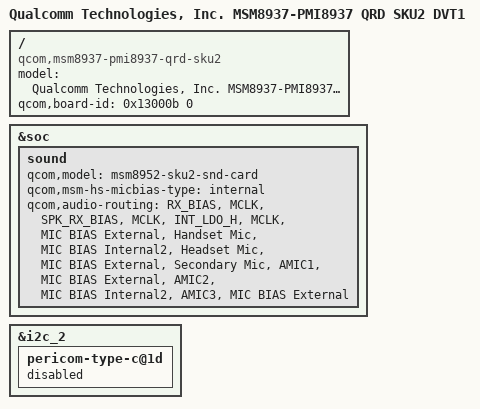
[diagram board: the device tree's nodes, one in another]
/*
 * Copyright (c) 2015, The Linux Foundation. All rights reserved.
 *
 * This program is free software; you can redistribute it and/or modify
 * it under the terms of the GNU General Public License version 2 and
 * only version 2 as published by the Free Software Foundation.
 *
 * This program is distributed in the hope that it will be useful,
 * but WITHOUT ANY WARRANTY; without even the implied warranty of
 * MERCHANTABILITY or FITNESS FOR A PARTICULAR PURPOSE.  See the
 * GNU General Public License for more details.
 */

/dts-v1/;

#include "msm8937.dtsi"
#include "msm8937-pmi8937-qrd-sku2.dtsi"

/ {
	model = "Qualcomm Technologies, Inc. MSM8937-PMI8937 QRD SKU2 DVT1";
	compatible = "qcom,msm8937-pmi8937-qrd-sku2",
		   "qcom,msm8937-qrd", "qcom,msm8937", "qcom,qrd";
	qcom,board-id= <0x13000b 0>;
};

&soc {
	sound {
		qcom,model = "msm8952-sku2-snd-card";
		qcom,msm-hs-micbias-type = "internal";
		qcom,audio-routing =
			"RX_BIAS", "MCLK",
			"SPK_RX_BIAS", "MCLK",
			"INT_LDO_H", "MCLK",
			"MIC BIAS External", "Handset Mic",
			"MIC BIAS Internal2", "Headset Mic",
			"MIC BIAS External", "Secondary Mic",
			"AMIC1", "MIC BIAS External",
			"AMIC2", "MIC BIAS Internal2",
			"AMIC3", "MIC BIAS External";
	};
};

&i2c_2 {
	pericom-type-c@1d {
		status="disabled";
	};
};
